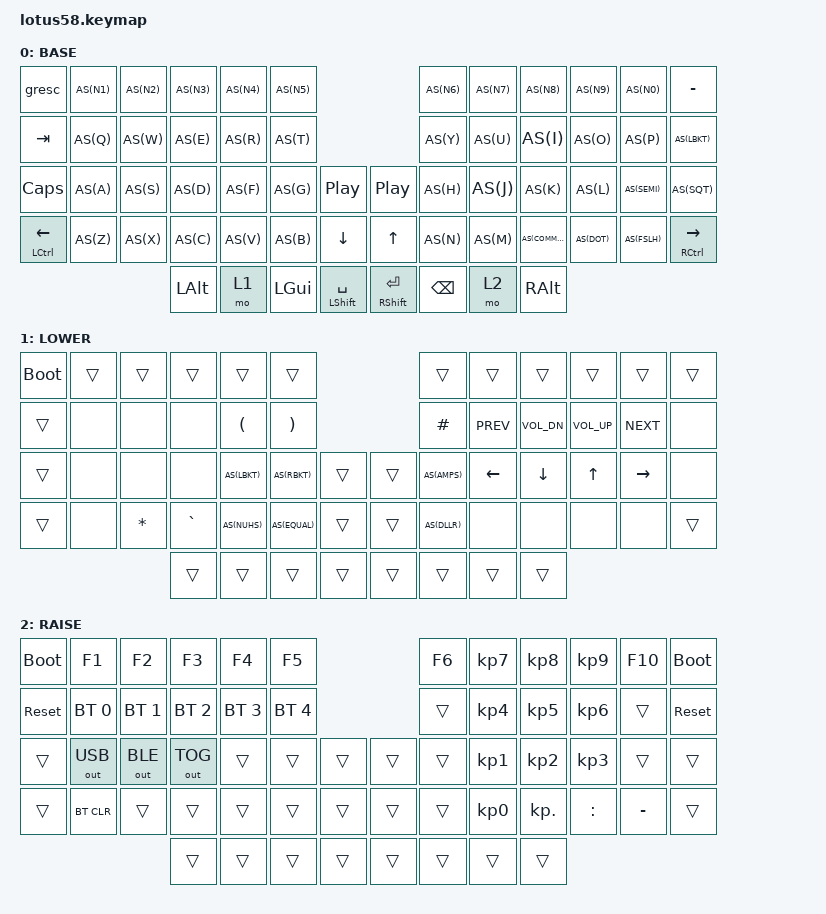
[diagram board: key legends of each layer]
#include <behaviors.dtsi>
#include <dt-bindings/zmk/keys.h>
#include <dt-bindings/zmk/bt.h>
#include <dt-bindings/zmk/outputs.h>

// Lotus58 Keyboard with 58 keys split design
// Features: OLED displays, 2 rotary encoders, 3 layers, auto-shift
// Bluetooth and USB connectivity with status display and battery indication

// Base Layer:
// ,-----------------------------------------.                              ,-----------------------------------------.
// | ESC  |  1   |  2   |  3   |  4   |  5   |                            |  6   |  7   |  8   |  9   |  0   |  -   |
// |------+------+------+------+------+------|                            |------+------+------+------+------+------|
// | Tab  |  Q   |  W   |  E   |  R   |  T   |                            |  Y   |  U   |  I   |  O   |  P   |  [   |
// |------+------+------+------+------+------+-------------.  ,------------+------+------+------+------+------+------|
// | Caps |  A   |  S   |  D   |  F   |  G   | Play/Pause |  | Play/Pause|  H   |  J   |  K   |  L   |  ;   |  '   |
// |------+------+------+------+------+------+------+------|  |------+----+------+------+------+------+------+------|
// | Ctrl |  Z   |  X   |  C   |  V   |  B   | Down |  Up  |  |  Up  |Down|  N   |  M   |  ,   |  .   |  /   |Ctrl |
// `----------------------------------------+------+------+--|  |--+------+------+-----------------------------------------'
//                                   | Alt  |Lower |  GUI | Space| Enter| Bksp |Raise | Alt  |
//                                   `--------------------+------+------+------'

// Lower Layer:
// ,-----------------------------------------.                              ,-----------------------------------------.
// | Boot |      |      |      |      |      |                            |      |      |      |      |      |      |
// |------+------+------+------+------+------|                            |------+------+------+------+------+------|
// |      |      |      |      |  (   |  )   |                            |  #   |Prev  |VolDn |VolUp |Next  |      |
// |------+------+------+------+------+------+-------------.  ,------------+------+------+------+------+------+------|
// |      |      |      |      |  [   |  ]   |      |      |  |      |     |  &   |Left  |Down  | Up   |Right |      |
// |------+------+------+------+------+------+------+------|  |------+----+------+------+------+------+------+------|
// |      |      |  *   |  `   |  \   |  =   |      |      |  |      |     |  $   |      |      |      |      |      |
// `----------------------------------------+------+------+--|  |--+------+------+-----------------------------------------'
//                                   |      |      |      |      |      |      |      |      |
//                                   `--------------------+------+------+------'

// Raise Layer:
// ,-----------------------------------------.                              ,-----------------------------------------.
// | Boot |  F1  |  F2  |  F3  |  F4  |  F5  |                            |  F6  |  7   |  8   |  9   | F10  | Boot |
// |------+------+------+------+------+------|                            |------+------+------+------+------+------|
// |Reset |BT 0  |BT 1  |BT 2  |BT 3  |BT 4  |                            |      |  4   |  5   |  6   |      |Reset |
// |------+------+------+------+------+------+-------------.  ,------------+------+------+------+------+------+------|
// |      | USB  | BLE  |OutTog|      |      |      |      |  |      |     |      |  1   |  2   |  3   |      |      |
// |------+------+------+------+------+------+------+------|  |------+----+------+------+------+------+------+------|
// |      |BTClr |      |      |      |      |      |      |  |      |     |      |  0   |  .   |  :   |  -   |      |
// `----------------------------------------+------+------+--|  |--+------+------+-----------------------------------------'
//                                   |      |      |      |      |      |      |      |      |
//                                   `--------------------+------+------+------'

#define AS(keycode) &as LS(keycode) keycode
/ {
    chosen {
        zmk,display = &oled;
    };

    behaviors {
        as: auto_shift {
            compatible = "zmk,behavior-hold-tap";
            label = "AUTO_SHIFT";
            #binding-cells = <2>;
            tapping_term_ms = <300>;
            quick_tap_ms = <0>;
            flavor = "tap-preferred";
            bindings = <&kp>, <&kp>;
        };
        gresc: grave_escape {
            compatible = "zmk,behavior-mod-morph";
            label = "GRAVE_ESCAPE";
            #binding-cells = <0>;
            bindings = <&kp ESC>, <&kp GRAVE>;
            mods = <(MOD_LGUI|MOD_LSFT|MOD_RGUI|MOD_RSFT)>;
            keep-mods = <(MOD_LSFT|MOD_RSFT)>;
        };
    };

    // Display configuration
    custom_status: custom_status {
        compatible = "zmk,widget-layer-status";
        label = "CUSTOM_STATUS";
    };

    keymap {
        compatible = "zmk,keymap";

        default_layer {
            label = "BASE";
            bindings = <
                &gresc   AS(N1)   AS(N2)   AS(N3)   AS(N4)   AS(N5)                               AS(N6)   AS(N7)   AS(N8)    AS(N9)   AS(N0)    &kp MINUS
                &kp TAB    AS(Q)    AS(W)    AS(E)    AS(R)    AS(T)                                AS(Y)    AS(U)    AS(I)     AS(O)    AS(P)     AS(LBKT)
                &kp CAPS   AS(A)    AS(S)    AS(D)    AS(F)    AS(G)    &kp C_PP         &kp C_PP  AS(H)    AS(J)    AS(K)     AS(L)    AS(SEMI)  AS(SQT)
                &mt LCTRL LEFT AS(Z) AS(X)   AS(C)    AS(V)    AS(B)    &kp DOWN         &kp UP    AS(N)    AS(M)    AS(COMMA) AS(DOT)  AS(FSLH)  &mt RCTRL RIGHT
                                            &kp LALT  &mo 1    &kp LGUI &mt LSHFT SPACE  &mt RSHFT RET &kp BSPC &mo 2    &kp RALT
            >;

            sensor-bindings = <&inc_dec_kp C_VOL_UP C_VOL_DN &inc_dec_kp C_VOL_UP C_VOL_DN>;
        };

        lower_layer {
            label = "LOWER";
            bindings = <
                &bootloader &trans   &trans   &trans    &trans    &trans                              &trans   &trans   &trans    &trans   &trans    &trans
                &trans     &none    &none    &none     &kp LPAR  &kp RPAR                           &kp HASH &kp C_PREV &kp C_VOL_DN &kp C_VOL_UP &kp C_NEXT &none
                &trans     &none    &none    &none     AS(LBKT)  AS(RBKT)  &trans          &trans   AS(AMPS) &kp LEFT &kp DOWN  &kp UP   &kp RIGHT &none 
                &trans     &none    &kp STAR &kp GRAVE AS(NUHS)  AS(EQUAL) &trans          &trans   AS(DLLR) &none    &none     &none    &none     &trans
                                            &trans    &trans    &trans    &trans          &trans   &trans   &trans   &trans
            >;

            sensor-bindings = <&inc_dec_kp C_VOL_UP C_VOL_DN &inc_dec_kp C_VOL_UP C_VOL_DN>;
        };

        raise_layer {
            label = "RAISE";
            bindings = <
                &bootloader &kp F1   &kp F2   &kp F3    &kp F4    &kp F5                             &kp F6   &kp KP_N7 &kp KP_N8 &kp KP_N9 &kp F10   &bootloader
                &sys_reset  &bt BT_SEL 0 &bt BT_SEL 1 &bt BT_SEL 2 &bt BT_SEL 3 &bt BT_SEL 4        &trans   &kp KP_N4 &kp KP_N5 &kp KP_N6 &trans    &sys_reset
                &trans     &out OUT_USB &out OUT_BLE &out OUT_TOG &trans &trans &trans       &trans  &trans   &kp KP_N1 &kp KP_N2 &kp KP_N3 &trans    &trans
                &trans     &bt BT_CLR &trans   &trans    &trans    &trans   &trans          &trans   &trans   &kp KP_N0 &kp KP_DOT &kp COLON &kp MINUS &trans
                                            &trans    &trans    &trans   &trans          &trans    &trans   &trans    &trans
            >;

            sensor-bindings = <&inc_dec_kp C_VOL_UP C_VOL_DN &inc_dec_kp C_VOL_UP C_VOL_DN>;
        };
    };
};

&oled {
    status = "okay";

    display_widgets {
        compatible = "zmk,display-widgets";
        
        layer_status_widget: layer_status_widget {
            compatible = "zmk,widget-layer-status";
            position = <0 0>;
        };

        keyboard_status: keyboard_status {
            compatible = "zmk,widget-battery-status";
            position = <0 16>;
        };

        output_status: output_status {
            compatible = "zmk,widget-output-status";
            position = <0 32>;
        };
    };
};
